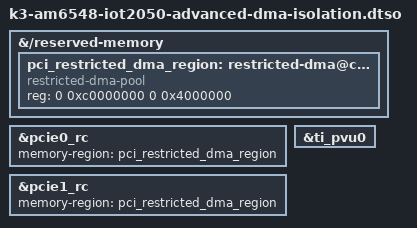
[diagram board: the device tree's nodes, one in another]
// SPDX-License-Identifier: GPL-2.0
/*
 * IOT2050, overlay for isolating DMA requests via PVU
 * Copyright (c) Siemens AG, 2024
 *
 * Authors:
 *   Jan Kiszka <jan.kiszka@siemens.com>
 */

/dts-v1/;
/plugin/;

&{/reserved-memory} {
	#address-cells = <2>;
	#size-cells = <2>;

	pci_restricted_dma_region: restricted-dma@c0000000 {
		compatible = "restricted-dma-pool";
		reg = <0 0xc0000000 0 0x4000000>;
	};
};

&pcie0_rc {
	memory-region = <&pci_restricted_dma_region>;
};

&pcie1_rc {
	memory-region = <&pci_restricted_dma_region>;
};

&ti_pvu0 {
	status = "okay";
};
